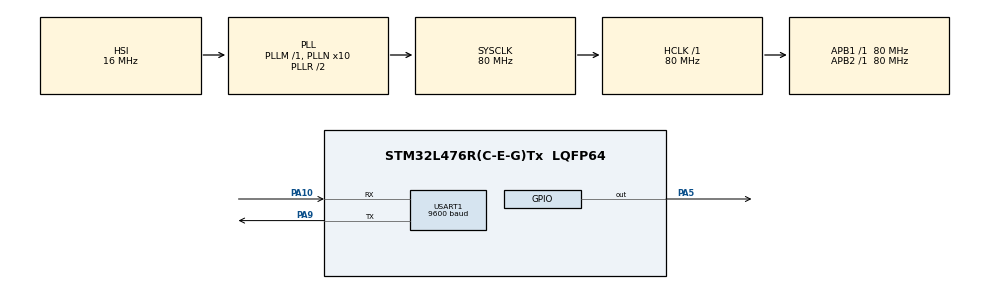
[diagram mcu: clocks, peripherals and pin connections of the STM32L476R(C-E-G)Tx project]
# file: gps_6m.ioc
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Dma.Request0=USART1_RX
Dma.USART1_RX.0.Direction=DMA_PERIPH_TO_MEMORY
Dma.USART1_RX.0.Instance=DMA1_Channel5
Dma.USART1_RX.0.MemDataAlignment=DMA_MDATAALIGN_BYTE
Dma.USART1_RX.0.MemInc=DMA_MINC_ENABLE
Dma.USART1_RX.0.Mode=DMA_CIRCULAR
Dma.USART1_RX.0.PeriphDataAlignment=DMA_PDATAALIGN_BYTE
Dma.USART1_RX.0.PeriphInc=DMA_PINC_DISABLE
Dma.USART1_RX.0.Priority=DMA_PRIORITY_LOW
Mcu.Family=STM32L4
Mcu.Name=STM32L476R(C-E-G)Tx
Mcu.Package=LQFP64
NVIC.DMA1_Channel5_IRQn=true\:0\:0\:false\:false\:true\:false\:true\:true
NVIC.PriorityGroup=NVIC_PRIORITYGROUP_4
PA10.Mode=Asynchronous
PA10.Signal=USART1_RX
PA13\ (JTMS-SWDIO).Mode=Serial_Wire
PA13\ (JTMS-SWDIO).Signal=SYS_JTMS-SWDIO
PA14\ (JTCK-SWCLK).Mode=Serial_Wire
PA14\ (JTCK-SWCLK).Signal=SYS_JTCK-SWCLK
PA5.Signal=GPIO_Output
PA9.Mode=Asynchronous
PA9.Signal=USART1_TX
PC14-OSC32_IN\ (PC14).Mode=LSE-External-Oscillator
PC14-OSC32_IN\ (PC14).Signal=RCC_OSC32_IN
PC15-OSC32_OUT\ (PC15).Mode=LSE-External-Oscillator
PC15-OSC32_OUT\ (PC15).Signal=RCC_OSC32_OUT
PH0-OSC_IN\ (PH0).Mode=HSE-External-Oscillator
PH0-OSC_IN\ (PH0).Signal=RCC_OSC_IN
PH1-OSC_OUT\ (PH1).Mode=HSE-External-Oscillator
PH1-OSC_OUT\ (PH1).Signal=RCC_OSC_OUT
ProjectManager.HeapSize=0x200
ProjectManager.StackSize=0x400
ProjectManager.TargetToolchain=STM32CubeIDE
RCC.ADCFreq_Value=64000000
RCC.AHBFreq_Value=80000000
RCC.APB1Freq_Value=80000000
RCC.APB1TimFreq_Value=80000000
RCC.APB2Freq_Value=80000000
RCC.APB2TimFreq_Value=80000000
RCC.CortexFreq_Value=80000000
RCC.HCLKFreq_Value=80000000
RCC.HSE_VALUE=8000000
RCC.HSI_VALUE=16000000
RCC.MSI_VALUE=4000000
RCC.PLLN=10
RCC.PLLSourceVirtual=RCC_PLLSOURCE_HSI
RCC.PREFETCH_ENABLE=1
RCC.SYSCLKFreq_VALUE=80000000
RCC.SYSCLKSource=RCC_SYSCLKSOURCE_PLLCLK
RCC.USBFreq_Value=64000000
RCC.VCOOutputFreq_Value=160000000
USART1.BaudRate=9600
USART1.VirtualMode-Asynchronous=VM_ASYNC
board=NUCLEO-L476RG

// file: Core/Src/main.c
/* USER CODE BEGIN Header */
/**
  ******************************************************************************
  * @file           : main.c
  * @brief          : Main program body
  ******************************************************************************
  * @attention
  *
  * Copyright (c) 2024 STMicroelectronics.
  * All rights reserved.
  *
  * This software is licensed under terms that can be found in the LICENSE file
  * in the root directory of this software component.
  * If no LICENSE file comes with this software, it is provided AS-IS.
  *
  ******************************************************************************
  */
/* USER CODE END Header */
#include "main.h"

/* USER CODE BEGIN Includes */
#include<stdio.h>
#include<stdlib.h>
#include<string.h>
int _write(int file,char *ptr,int len)
{
    int i=0;
    for(i=0;i<len;i++)
      ITM_SendChar((*ptr++));
    return len;
}
/* USER CODE END Includes */

UART_HandleTypeDef huart1;
DMA_HandleTypeDef hdma_usart1_rx;

/* USER CODE BEGIN PV */
 uint8_t Rxdata[750];
 char Txdata[750];
 char GPS_Payload[100];
 uint8_t Flag=0;
 static int Msgindex;
 char *ptr;

 float time, Latitude, Longtitude;
 int Hours,Min,Sec;

/* USER CODE END PV */

void SystemClock_Config(void);
static void MX_GPIO_Init(void);
static void MX_DMA_Init(void);
static void MX_USART1_UART_Init(void);
/* USER CODE BEGIN PFP */

void get_location(void);
void Format_data(float Time, float Lat , float Long );

/* USER CODE END PFP */

int main(void)
{

  /* MCU Configuration--------------------------------------------------------*/

  /* Reset of all peripherals, Initializes the Flash interface and the Systick. */
  HAL_Init();

  /* Configure the system clock */
  SystemClock_Config();

  /* Initialize all configured peripherals */
  MX_GPIO_Init();
  MX_DMA_Init();
  MX_USART1_UART_Init();
  /* USER CODE BEGIN 2 */
  HAL_UART_Receive_DMA(&huart1,(uint8_t *)Rxdata,700);
  /* USER CODE END 2 */
  int count  = 0;
  /* Infinite loop */
  while (1)
  {

    /* USER CODE BEGIN 3 */
	  printf("%d\n",count);
	  get_location();
	  HAL_GPIO_TogglePin(GPIOA, GPIO_PIN_5);
	  printf("%d\n",count++);
	  HAL_Delay(1000);

  }
  /* USER CODE END 3 */
}

void SystemClock_Config(void)
{
  RCC_OscInitTypeDef RCC_OscInitStruct = {0};
  RCC_ClkInitTypeDef RCC_ClkInitStruct = {0};

  /** Configure the main internal regulator output voltage
  */
  if (HAL_PWREx_ControlVoltageScaling(PWR_REGULATOR_VOLTAGE_SCALE1) != HAL_OK)
  {
    Error_Handler();
  }

  /** Initializes the RCC Oscillators according to the specified parameters
  * in the RCC_OscInitTypeDef structure.
  */
  RCC_OscInitStruct.OscillatorType = RCC_OSCILLATORTYPE_HSI;
  RCC_OscInitStruct.HSIState = RCC_HSI_ON;
  RCC_OscInitStruct.HSICalibrationValue = RCC_HSICALIBRATION_DEFAULT;
  RCC_OscInitStruct.PLL.PLLState = RCC_PLL_ON;
  RCC_OscInitStruct.PLL.PLLSource = RCC_PLLSOURCE_HSI;
  RCC_OscInitStruct.PLL.PLLM = 1;
  RCC_OscInitStruct.PLL.PLLN = 10;
  RCC_OscInitStruct.PLL.PLLP = RCC_PLLP_DIV7;
  RCC_OscInitStruct.PLL.PLLQ = RCC_PLLQ_DIV2;
  RCC_OscInitStruct.PLL.PLLR = RCC_PLLR_DIV2;
  if (HAL_RCC_OscConfig(&RCC_OscInitStruct) != HAL_OK)
  {
    Error_Handler();
  }

  /** Initializes the CPU, AHB and APB buses clocks
  */
  RCC_ClkInitStruct.ClockType = RCC_CLOCKTYPE_HCLK|RCC_CLOCKTYPE_SYSCLK
                              |RCC_CLOCKTYPE_PCLK1|RCC_CLOCKTYPE_PCLK2;
  RCC_ClkInitStruct.SYSCLKSource = RCC_SYSCLKSOURCE_PLLCLK;
  RCC_ClkInitStruct.AHBCLKDivider = RCC_SYSCLK_DIV1;
  RCC_ClkInitStruct.APB1CLKDivider = RCC_HCLK_DIV1;
  RCC_ClkInitStruct.APB2CLKDivider = RCC_HCLK_DIV1;

  if (HAL_RCC_ClockConfig(&RCC_ClkInitStruct, FLASH_LATENCY_4) != HAL_OK)
  {
    Error_Handler();
  }
}

static void MX_USART1_UART_Init(void)
{

  huart1.Instance = USART1;
  huart1.Init.BaudRate = 9600;
  huart1.Init.WordLength = UART_WORDLENGTH_8B;
  huart1.Init.StopBits = UART_STOPBITS_1;
  huart1.Init.Parity = UART_PARITY_NONE;
  huart1.Init.Mode = UART_MODE_TX_RX;
  huart1.Init.HwFlowCtl = UART_HWCONTROL_NONE;
  huart1.Init.OverSampling = UART_OVERSAMPLING_16;
  huart1.Init.OneBitSampling = UART_ONE_BIT_SAMPLE_DISABLE;
  huart1.AdvancedInit.AdvFeatureInit = UART_ADVFEATURE_NO_INIT;
  if (HAL_UART_Init(&huart1) != HAL_OK)
  {
    Error_Handler();
  }

}

static void MX_DMA_Init(void)
{

  /* DMA controller clock enable */
  __HAL_RCC_DMA1_CLK_ENABLE();

  /* DMA interrupt init */
  /* DMA1_Channel5_IRQn interrupt configuration */
  HAL_NVIC_SetPriority(DMA1_Channel5_IRQn, 0, 0);
  HAL_NVIC_EnableIRQ(DMA1_Channel5_IRQn);

}

static void MX_GPIO_Init(void)
{
  GPIO_InitTypeDef GPIO_InitStruct = {0};

  /* GPIO Ports Clock Enable */
  __HAL_RCC_GPIOC_CLK_ENABLE();
  __HAL_RCC_GPIOH_CLK_ENABLE();
  __HAL_RCC_GPIOA_CLK_ENABLE();

  /*Configure GPIO pin Output Level */
  HAL_GPIO_WritePin(GPIOA, GPIO_PIN_5, GPIO_PIN_RESET);

  /*Configure GPIO pin : PA5 */
  GPIO_InitStruct.Pin = GPIO_PIN_5;
  GPIO_InitStruct.Mode = GPIO_MODE_OUTPUT_PP;
  GPIO_InitStruct.Pull = GPIO_NOPULL;
  GPIO_InitStruct.Speed = GPIO_SPEED_FREQ_LOW;
  HAL_GPIO_Init(GPIOA, &GPIO_InitStruct);

}

/* USER CODE BEGIN 4 */
void HAL_UART_RxxpltCallback(UART_HandleTypeDef *huart)
{
	Flag=1;
}

void get_location(void)
{
	if(Flag ==1)
	{
		Msgindex =0;
		strcpy(Txdata,(char*)(Rxdata));
		printf("%s\n",Rxdata);
		ptr=strstr(Txdata,"GPRMC");
		if(*ptr=='G')
		{
			while(1)
			{
				GPS_Payload[Msgindex]=*ptr;
				Msgindex++;
				*ptr = *(ptr+Msgindex);

				if(*ptr == '\n')
				{
					GPS_Payload[Msgindex]='\0';
					break;
				}
			}
			sscanf(GPS_Payload,"GPRMC,%f,A,%f,N,%f,",&time,&Latitude,&Longtitude);
			Format_data(time, Latitude, Longtitude);
			HAL_Delay(1);
			Flag=0;

		}
		else
			memset(Rxdata,0,sizeof(Rxdata));
	}
}

void Format_data(float Time ,float Lat , float Long)
{
	char Data[100];
	Hours = (int)Time/10000;
	Min   = (int)(Time -(Hours * 10000))/100;
	Sec   = (int)(Time -((Hours * 10000)+(Min * 100)));
	printf("%s",Data);
}

/* USER CODE END 4 */

void Error_Handler(void)
{
  __disable_irq();
  while (1)
  {
  }
}
